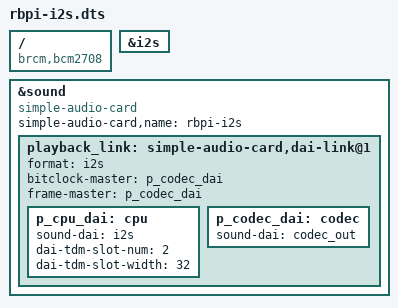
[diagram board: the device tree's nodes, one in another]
/dts-v1/;
/plugin/;

/ {
    compatible = "brcm,bcm2708";

    fragment@0 {
        target = <&i2s>;
        __overlay__ {
            status = "okay";
        };
    };

 
    fragment@1 {
        target = <&sound>;
        __overlay__ {
            compatible = "simple-audio-card";
            simple-audio-card,name = "rbpi-i2s";
            status = "okay";

            playback_link: simple-audio-card,dai-link@1 {
                format = "i2s";
                bitclock-master = <&p_codec_dai>;
                frame-master = <&p_codec_dai>;
            
                p_cpu_dai: cpu {
                    sound-dai = <&i2s>;
                    dai-tdm-slot-num = <2>;
                    dai-tdm-slot-width = <32>;
                };
                
                p_codec_dai: codec {
                    sound-dai = <&codec_out>;
                };
            };
        };
    };
};
